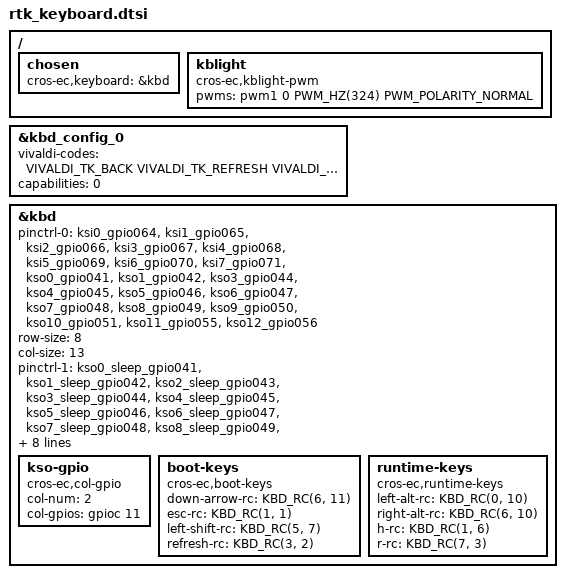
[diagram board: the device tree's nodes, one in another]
/* Copyright 2025 The ChromiumOS Authors
 * Use of this source code is governed by a BSD-style license that can be
 * found in the LICENSE file.
 */

/ {
	chosen {
		cros-ec,keyboard = &kbd;
	};

	kblight: kblight {
		compatible = "cros-ec,kblight-pwm";
		pwms = <&pwm1 0 PWM_HZ(324) PWM_POLARITY_NORMAL>;
	};
};

&kbd_config_0 {
	vivaldi-codes = <
		VIVALDI_TK_BACK              /* T1 */
		VIVALDI_TK_REFRESH           /* T2 */
		VIVALDI_TK_FULLSCREEN        /* T3 */
		VIVALDI_TK_OVERVIEW          /* T4 */
		VIVALDI_TK_SNAPSHOT          /* T5 */
		VIVALDI_TK_BRIGHTNESS_DOWN   /* T6 */
		VIVALDI_TK_BRIGHTNESS_UP     /* T7 */
		VIVALDI_TK_VOL_MUTE          /* T8 */
		VIVALDI_TK_VOL_DOWN          /* T9 */
		VIVALDI_TK_VOL_UP            /* T10 */
	>;
	capabilities = <0>;                  /* No lock button */
};

&kbd {
	status = "okay";
	pinctrl-0 = <
		&ksi0_gpio064
		&ksi1_gpio065
		&ksi2_gpio066
		&ksi3_gpio067
		&ksi4_gpio068
		&ksi5_gpio069
		&ksi6_gpio070
		&ksi7_gpio071
		&kso0_gpio041
		&kso1_gpio042
		&kso3_gpio044
		&kso4_gpio045
		&kso5_gpio046
		&kso6_gpio047
		&kso7_gpio048
		&kso8_gpio049
		&kso9_gpio050
		&kso10_gpio051
		&kso11_gpio055
		&kso12_gpio056
	>;
	row-size = <8>;
	col-size = <13>;
	pinctrl-1 = <&kso0_sleep_gpio041 &kso1_sleep_gpio042
				 &kso2_sleep_gpio043 &kso3_sleep_gpio044
				 &kso4_sleep_gpio045 &kso5_sleep_gpio046
				 &kso6_sleep_gpio047 &kso7_sleep_gpio048
				 &kso8_sleep_gpio049 &kso9_sleep_gpio050
				 &kso10_sleep_gpio051 &kso11_sleep_gpio055
				 &kso12_sleep_gpio056 &kso13_sleep_gpio057
				 &kso14_sleep_gpio058 &kso15_sleep_gpio059
				 &ksi0_gpio064 &ksi1_gpio065
				 &ksi2_gpio066 &ksi3_gpio067
				 &ksi4_gpio068 &ksi5_gpio069
				 &ksi6_gpio070 &ksi7_gpio071>;
	pinctrl-names = "default", "sleep";
	kso-ignore-mask = <04>;

	kso-gpio {
		compatible = "cros-ec,col-gpio";
		col-num = <2>;
		col-gpios = <&gpioc 11 GPIO_ACTIVE_HIGH>;
	};

	boot-keys {
		compatible = "cros-ec,boot-keys";
		down-arrow-rc = <KBD_RC(6, 11)>;
		esc-rc = <KBD_RC(1, 1)>;
		left-shift-rc = <KBD_RC(5, 7)>;
		refresh-rc = <KBD_RC(3, 2)>;
	};

	runtime-keys {
		compatible = "cros-ec,runtime-keys";
		left-alt-rc = <KBD_RC(0, 10)>;
		right-alt-rc = <KBD_RC(6, 10)>;
		h-rc = <KBD_RC(1, 6)>;
		r-rc = <KBD_RC(7, 3)>;
	};
};
